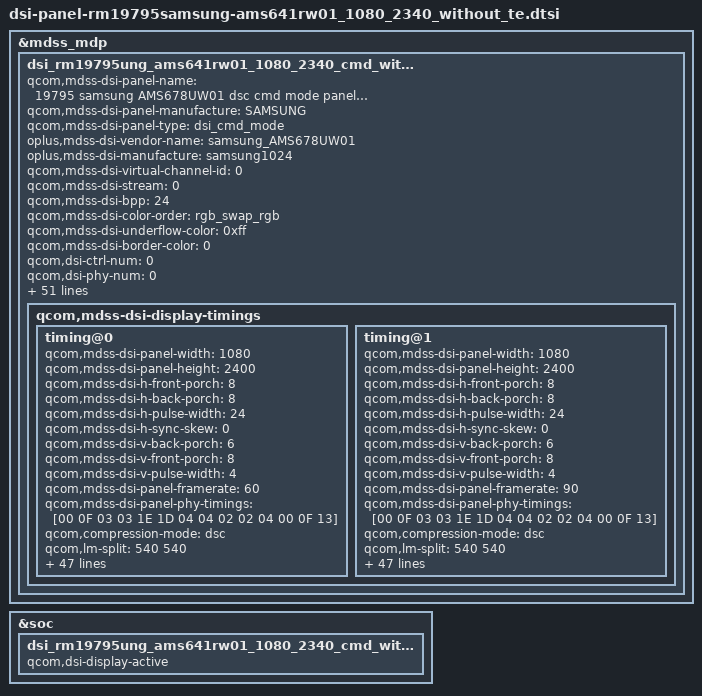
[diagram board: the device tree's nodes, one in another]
&mdss_mdp {
	dsi_rm19795ung_ams641rw01_1080_2340_cmd_without_te: qcom,mdss_dsi_rm19795samsung_ams641rw01_1080_2340_cmd_no_te {
		qcom,mdss-dsi-panel-name = "19795 samsung AMS678UW01 dsc cmd mode panel Without TE";
		qcom,mdss-dsi-panel-manufacture = "SAMSUNG";
		qcom,mdss-dsi-panel-type = "dsi_cmd_mode";
		oplus,mdss-dsi-vendor-name = "samsung_AMS678UW01";
		oplus,mdss-dsi-manufacture = "samsung1024";
		qcom,mdss-dsi-virtual-channel-id = <0>;
		qcom,mdss-dsi-stream = <0>;
		qcom,mdss-dsi-bpp = <24>;
		qcom,mdss-dsi-color-order = "rgb_swap_rgb";
		qcom,mdss-dsi-underflow-color = <0xff>;
		qcom,mdss-dsi-border-color = <0>;
		qcom,dsi-ctrl-num = <0>;
		qcom,dsi-phy-num = <0>;
		qcom,mdss-dsi-traffic-mode = "burst_mode";
		qcom,mdss-dsi-lane-map = "lane_map_0123";
		qcom,mdss-dsi-bllp-eof-power-mode;
		qcom,mdss-dsi-bllp-power-mode;
		qcom,mdss-dsi-lane-0-state;
		qcom,mdss-dsi-lane-1-state;
		qcom,mdss-dsi-lane-2-state;
		qcom,mdss-dsi-lane-3-state;
		qcom,mdss-dsi-dma-trigger = "trigger_sw";
		qcom,mdss-dsi-mdp-trigger = "none";
		qcom,mdss-dsi-reset-sequence = <1 20>, <0 10>, <1 5>;
		qcom,mdss-pan-physical-width-dimension = <71>;
		qcom,mdss-pan-physical-height-dimension = <157>;
		qcom,mdss-dsi-init-delay-us = <1000>;
		qcom,mdss-dsi-lp11-init;
		qcom,mdss-dsi-wr-mem-start = <0x2c>;
		qcom,mdss-dsi-wr-mem-continue = <0x3c>;
		qcom,mdss-dsi-te-dcs-command = <1>;
		/* HDR Setting */
		qcom,mdss-dsi-panel-hdr-enabled;
		qcom,mdss-dsi-panel-hdr-color-primaries = <15635 16450 34000 16000 13250 34500 7500 3000>;
		qcom,mdss-dsi-panel-peak-brightness = <5400000>;
		qcom,mdss-dsi-panel-average-brightness = <2000000>;
		qcom,mdss-dsi-panel-blackness-level = <2000>;

		qcom,mdss-dsi-te-using-wd;
		qcom,mdss-dsi-te-using-te-pin;
 		qcom,mdss-dsi-te-pin-select = <1>;
 
		//qcom,esd-check-enabled;
		//qcom,mdss-dsi-panel-status-check-mode = "reg_read";
		//qcom,mdss-dsi-panel-status-command = [06 01 00 01 05 00 02 0A 00];
		//qcom,mdss-dsi-panel-status-command-state = "dsi_lp_mode";
		//qcom,mdss-dsi-panel-status-value = <0x9C>;
		//qcom,mdss-dsi-panel-status-read-length = <1>;

		qcom,dynamic-mode-switch-enabled;
		qcom,dynamic-mode-switch-type = "dynamic-resolution-switch-immediate";
		qcom,mdss-dsi-display-timings {
			timing@0{
				//qcom,mdss-mdp-transfer-time-us = <14000>;
				//qcom,mdss-dsi-panel-clockrate = <1020000000>;
				qcom,mdss-dsi-panel-width = <1080>;
				qcom,mdss-dsi-panel-height = <2400>;
				qcom,mdss-dsi-h-front-porch = <8>;
				qcom,mdss-dsi-h-back-porch = <8>;
				qcom,mdss-dsi-h-pulse-width = <24>;
				qcom,mdss-dsi-h-sync-skew = <0>;
				qcom,mdss-dsi-v-back-porch = <6>;
				qcom,mdss-dsi-v-front-porch = <8>;
				qcom,mdss-dsi-v-pulse-width = <4>;
				qcom,mdss-dsi-panel-framerate = <60>;
				qcom,mdss-dsi-panel-phy-timings = [00 0F 03 03 1E 1D 04 04 02 02 04 00 0F 13];
				//qcom,display-topology = <2 2 1>;
				//qcom,default-topology-index = <0>;

				qcom,compression-mode = "dsc";
				qcom,lm-split = <540 540>;
				qcom,mdss-dsc-encoders = <2>;
				qcom,mdss-dsc-slice-height = <48>;
				qcom,mdss-dsc-slice-width = <540>;
				qcom,mdss-dsc-slice-per-pkt = <2>;
				qcom,mdss-dsc-bit-per-component = <8>;
				qcom,mdss-dsc-bit-per-pixel = <8>;
				qcom,mdss-dsc-block-prediction-enable;

				qcom,mdss-dsi-on-command = [
					//39 01 00 00 00 00 03 9F 5A 5A
					39 01 00 00 00 00 59 9E
					11 00 00 89 30 80 09 60
					04 38 00 30 02 1C 02 1C
					02 00 02 52 00 20 04 23
					00 07 00 0F 02 8E 02 1F
					18 00 10 F0 03 0C 20 00
					06 0B 0B 33 0E 1C 2A 38
					46 54 62 69 70 77 79 7B
					7D 7E 01 02 01 00 09 40
					09 BE 19 FC 19 FA 19 F8
					1A 38 1A 78 1A B6 2A B6
					2A F4 2A F4 4B 34 63 74
					39 01 00 00 00 00 02 9D 01
					//39 01 00 00 00 00 03 9F A5 A5

					05 01 00 00 14 00 01 11
					/* TE ON */
					39 01 00 00 00 00 02 35 00
					/* CASET/PASET Setting */
					39 01 00 00 00 00 05 2A 00 00 04 37
					39 01 00 00 00 00 05 2B 00 00 09 5F

					/* Dimming Setting */
					39 01 00 00 00 00 03 F0 5A 5A
					39 01 00 00 00 00 02 B0 06
					39 01 00 00 00 00 02 B7 01
					39 01 00 00 00 00 02 B0 05
					39 01 00 00 00 00 02 B7 13
					39 01 00 00 00 00 03 F0 A5 A5
					39 01 00 00 00 00 02 53 20
					/* 60hz Transition */
					39 01 00 00 00 00 03 F0 5A 5A
					39 01 00 00 00 00 02 60 00
					39 01 00 00 00 00 03 F0 A5 A5
					/* ACL Mode OFF */
					39 01 00 00 00 00 02 55 00
					/* Display On */
					05 01 00 00 00 00 01 29
				];
				qcom,mdss-dsi-off-command=[
					05 01 00 00 14 00 01 28
					05 01 00 00 96 00 01 10
				];
				qcom,mdss-dsi-timing-switch-command = [
					39 00 00 00 00 00 03 F0 5A 5A
					15 00 00 00 00 00 02 60 00					/* 60HZ */
					39 01 00 00 07 00 03 F0 A5 A5
				];
				qcom,mdss-dsi-lp1-command = [
					/* Aod Mode */
					39 01 00 00 00 00 03 F0 5A 5A
					15 01 00 00 00 00 02 6A 00
					15 01 00 00 00 00 02 53 22
					39 01 00 00 14 00 03 F0 A5 A5
				];
				qcom,mdss-dsi-nolp-command = [
					39 01 00 00 00 00 03 F0 5A 5A
					15 00 00 00 00 00 02 60 00 /*60HZ*/
					15 00 00 00 00 00 02 F7 0F
					39 01 00 00 00 00 03 F0 A5 A5
					/* Normal Mode */
					39 01 00 00 00 00 03 F0 5A 5A
					15 01 00 00 00 00 02 6A 00
					15 01 00 00 00 00 02 53 28
					39 01 00 00 00 00 03 F0 A5 A5
				];
				qcom,mdss-dsi-aod-hbm-on-command = [
					/* HBM Mode ON */
					39 01 00 00 00 00 02 53 E0
					/* 0xE0 Normal transition */
					39 01 00 00 00 00 03 51 05 93
				];
				qcom,mdss-dsi-aod-hbm-off-command = [
					15 01 00 00 00 00 02 53 22
					39 01 00 00 00 00 03 51 00 01
				];
				qcom,mdss-dsi-hbm-on-command = [
					15 01 00 00 00 00 02 53 E0
					39 01 00 00 00 00 03 51 05 93
				];
				qcom,mdss-dsi-normal-hbm-on-command = [
					15 01 00 00 00 00 02 53 E0
					39 01 00 00 00 00 03 51 07 FF
				];
				qcom,mdss-dsi-seed-off-command = [];
				qcom,mdss-dsi-seed-0-command = [];
				qcom,mdss-dsi-seed-1-command = [];
				qcom,mdss-dsi-seed-2-command = [];
				qcom,mdss-dsi-aod-hbm-on-command-state = "dsi_hs_mode";
				qcom,mdss-dsi-aod-hbm-off-command-state = "dsi_hs_mode";
				qcom,mdss-dsi-timing-switch-command-state = "dsi_hs_mode";
				qcom,mdss-dsi-on-command-state = "dsi_lp_mode";
				qcom,mdss-dsi-off-command-state = "dsi_hs_mode";
				qcom,mdss-dsi-seed-off-command-state = "dsi_hs_mode";
				qcom,mdss-dsi-seed-0-command-state = "dsi_hs_mode";
				qcom,mdss-dsi-seed-1-command-state = "dsi_hs_mode";
				qcom,mdss-dsi-seed-2-command-state = "dsi_hs_mode";
			};
			timing@1{
				//qcom,mdss-mdp-transfer-time-us = <14000>;
				//qcom,mdss-dsi-panel-clockrate = <1020000000>;
				qcom,mdss-dsi-panel-width = <1080>;
				qcom,mdss-dsi-panel-height = <2400>;
				qcom,mdss-dsi-h-front-porch = <8>;
				qcom,mdss-dsi-h-back-porch = <8>;
				qcom,mdss-dsi-h-pulse-width = <24>;
				qcom,mdss-dsi-h-sync-skew = <0>;
				qcom,mdss-dsi-v-back-porch = <6>;
				qcom,mdss-dsi-v-front-porch = <8>;
				qcom,mdss-dsi-v-pulse-width = <4>;
				qcom,mdss-dsi-panel-framerate = <90>;
				qcom,mdss-dsi-panel-phy-timings = [00 0F 03 03 1E 1D 04 04 02 02 04 00 0F 13];
				//qcom,display-topology = <2 2 1>;
				//qcom,default-topology-index = <0>;

				qcom,compression-mode = "dsc";
				qcom,lm-split = <540 540>;
				qcom,mdss-dsc-encoders = <2>;
				qcom,mdss-dsc-slice-height = <48>;
				qcom,mdss-dsc-slice-width = <540>;
				qcom,mdss-dsc-slice-per-pkt = <2>;
				qcom,mdss-dsc-bit-per-component = <8>;
				qcom,mdss-dsc-bit-per-pixel = <8>;
				qcom,mdss-dsc-block-prediction-enable;

				qcom,mdss-dsi-on-command = [
					//39 01 00 00 00 00 03 9F 5A 5A
					39 01 00 00 00 00 59 9E
					11 00 00 89 30 80 09 60
					04 38 00 30 02 1C 02 1C
					02 00 02 52 00 20 04 23
					00 07 00 0F 02 8E 02 1F
					18 00 10 F0 03 0C 20 00
					06 0B 0B 33 0E 1C 2A 38
					46 54 62 69 70 77 79 7B
					7D 7E 01 02 01 00 09 40
					09 BE 19 FC 19 FA 19 F8
					1A 38 1A 78 1A B6 2A B6
					2A F4 2A F4 4B 34 63 74
					39 01 00 00 00 00 02 9D 01
					//39 01 00 00 00 00 03 9F A5 A5

					05 01 00 00 14 00 01 11
					/* TE ON */
					39 01 00 00 00 00 02 35 00
					/* CASET/PASET Setting */
					39 01 00 00 00 00 05 2A 00 00 04 37
					39 01 00 00 00 00 05 2B 00 00 09 5F

					/* Dimming Setting */
					39 01 00 00 00 00 03 F0 5A 5A
					39 01 00 00 00 00 02 B0 06
					39 01 00 00 00 00 02 B7 01
					39 01 00 00 00 00 02 B0 05
					39 01 00 00 00 00 02 B7 13
					39 01 00 00 00 00 03 F0 A5 A5
					39 01 00 00 00 00 02 53 20
					/* 90hz Transition */
					39 01 00 00 00 00 03 F0 5A 5A
					39 01 00 00 00 00 02 60 10
					39 01 00 00 00 00 03 F0 A5 A5
					/* ACL Mode OFF */
					39 01 00 00 00 00 02 55 00
					/* Display On */
					05 01 00 00 00 00 01 29
				];
				qcom,mdss-dsi-off-command=[
					05 01 00 00 14 00 01 28
					05 01 00 00 96 00 01 10
				];
				qcom,mdss-dsi-timing-switch-command = [
					39 00 00 00 00 00 03 F0 5A 5A
					15 00 00 00 00 00 02 60 10					/* 90HZ */
					39 01 00 00 07 00 03 F0 A5 A5
				];
				qcom,mdss-dsi-lp1-command = [
					/* Aod Mode */
					39 01 00 00 00 00 03 F0 5A 5A
					15 01 00 00 00 00 02 6A 00
					15 01 00 00 00 00 02 53 22
					39 01 00 00 14 00 03 F0 A5 A5
				];
				qcom,mdss-dsi-nolp-command = [
					39 01 00 00 00 00 03 F0 5A 5A
					15 00 00 00 00 00 02 60 10 /*90HZ*/
					15 00 00 00 00 00 02 F7 0F
					39 01 00 00 00 00 03 F0 A5 A5
					/* Normal Mode */
					39 01 00 00 00 00 03 F0 5A 5A
					15 01 00 00 00 00 02 6A 00
					15 01 00 00 00 00 02 53 28
					39 01 00 00 00 00 03 F0 A5 A5
				];
				qcom,mdss-dsi-aod-hbm-on-command = [
					/* HBM Mode ON */
					39 01 00 00 00 00 02 53 E0
					/* 0xE0 Normal transition */
					39 01 00 00 00 00 03 51 05 93
				];
				qcom,mdss-dsi-aod-hbm-off-command = [
					15 01 00 00 00 00 02 53 22
					39 01 00 00 00 00 03 51 00 01
				];
				qcom,mdss-dsi-hbm-on-command = [
					15 01 00 00 00 00 02 53 E0
					39 01 00 00 00 00 03 51 05 93
				];
				qcom,mdss-dsi-normal-hbm-on-command = [
					15 01 00 00 00 00 02 53 E0
					39 01 00 00 00 00 03 51 07 FF
				];
				qcom,mdss-dsi-seed-off-command = [];
				qcom,mdss-dsi-seed-0-command = [];
				qcom,mdss-dsi-seed-1-command = [];
				qcom,mdss-dsi-seed-2-command = [];
				qcom,mdss-dsi-aod-hbm-on-command-state = "dsi_hs_mode";
				qcom,mdss-dsi-aod-hbm-off-command-state = "dsi_hs_mode";
				qcom,mdss-dsi-timing-switch-command-state = "dsi_hs_mode";
				qcom,mdss-dsi-on-command-state = "dsi_lp_mode";
				qcom,mdss-dsi-off-command-state = "dsi_hs_mode";
				qcom,mdss-dsi-seed-off-command-state = "dsi_hs_mode";
				qcom,mdss-dsi-seed-0-command-state = "dsi_hs_mode";
				qcom,mdss-dsi-seed-1-command-state = "dsi_hs_mode";
				qcom,mdss-dsi-seed-2-command-state = "dsi_hs_mode";
			};
		};
	};
};

&dsi_rm19795ung_ams641rw01_1080_2340_cmd_without_te {
	qcom,panel-supply-entries = <&dsi_panel_pwr_supply>;
	qcom,iris-supply-entries = <&dsi_iris_pwr_supply>;
	qcom,mdss-dsi-bl-pmic-control-type = "bl_ctrl_dcs";
	qcom,mdss-dsi-bl-min-level = <1>;
	qcom,mdss-dsi-bl-normal-max-level = <1023>;
	qcom,mdss-dsi-bl-max-level = <2047>;
	qcom,mdss-brightness-normal-max-level = <1023>;
	qcom,mdss-brightness-max-level = <2047>;
	qcom,mdss-brightness-default-level = <400>;
	qcom,platform-te-gpio = <&tlmm 66 0>;
	qcom,platform-reset-gpio = <&tlmm 75 0>;
	//#ifdefine VENDOR_EDIT
	//qcom,platform-panel-vout-gpio = <&tlmm 8 0>;
	//#endif /*VENDOR_EDIT*/
	//qcom,ulps-enabled;
	qcom,dsi-select-clocks = "mux_byte_clk0", "mux_pixel_clk0","pw_bb_clk2";

	qcom,mdss-dsi-display-timings {
		timing@0 { /* fhd 60hz */
				qcom,mdss-dsi-panel-phy-timings = [00 0F 03 03 1E 1D 04 04 02 02 04 00 0F 13];
			qcom,display-topology = <1 1 1>,<2 2 1>;
			qcom,default-topology-index = <1>;
		};
		timing@1 { /* fhd 90hz */
				qcom,mdss-dsi-panel-phy-timings = [00 0F 03 03 1E 1D 04 04 02 02 04 00 0F 13];
			qcom,display-topology = <1 1 1>,<2 2 1>;
			qcom,default-topology-index = <1>;
		};
	};
};

&soc {
	dsi_rm19795ung_ams641rw01_1080_2340_cmd_without_te_display{
		qcom,dsi-display-active;
	};
};


&dsi_rm19795ung_ams641rw01_1080_2340_cmd_without_te {
	qcom,platform-iris-reset-gpio = <&tlmm 174 0>;
	qcom,platform-iris-vdd-gpio = <&tlmm 175 0>;
	qcom,platform-analog-bypass-gpio = <&tlmm 173 0>;
	qcom,platform-analog-bypass-status-gpio = <&tlmm 112 0>;
};
